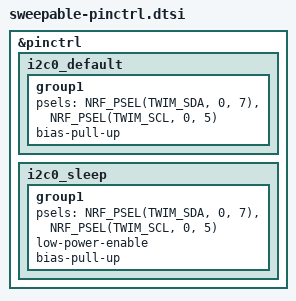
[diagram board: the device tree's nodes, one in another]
// Copyright (c) 2026 jack@pngu.org
// SPDX-License-Identifier: MIT

&pinctrl {
    i2c0_default: i2c0_default {
        group1 {
            psels = <NRF_PSEL(TWIM_SDA, 0, 7)>,
                    <NRF_PSEL(TWIM_SCL, 0, 5)>;
            bias-pull-up;
        };
    };

    i2c0_sleep: i2c0_sleep {
        group1 {
            psels = <NRF_PSEL(TWIM_SDA, 0, 7)>,
                    <NRF_PSEL(TWIM_SCL, 0, 5)>;
            low-power-enable;
            bias-pull-up;
        };
    };
};

